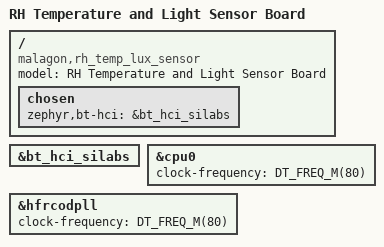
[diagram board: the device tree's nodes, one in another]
/dts-v1/;
#include <silabs/xg26/mgm260pd32vna.dtsi>
#include "rh_temp_lux_sensor.dtsi"

/ {
	model = "RH Temperature and Light Sensor Board";
	compatible = "malagon,rh_temp_lux_sensor", "silabs,mgm26";

	chosen {
		zephyr,bt-hci = &bt_hci_silabs;
	};
};

&bt_hci_silabs {
	status = "okay";
};

&cpu0 {
	clock-frequency = <DT_FREQ_M(80)>;
};

&hfrcodpll {
	clock-frequency = <DT_FREQ_M(80)>;
};
